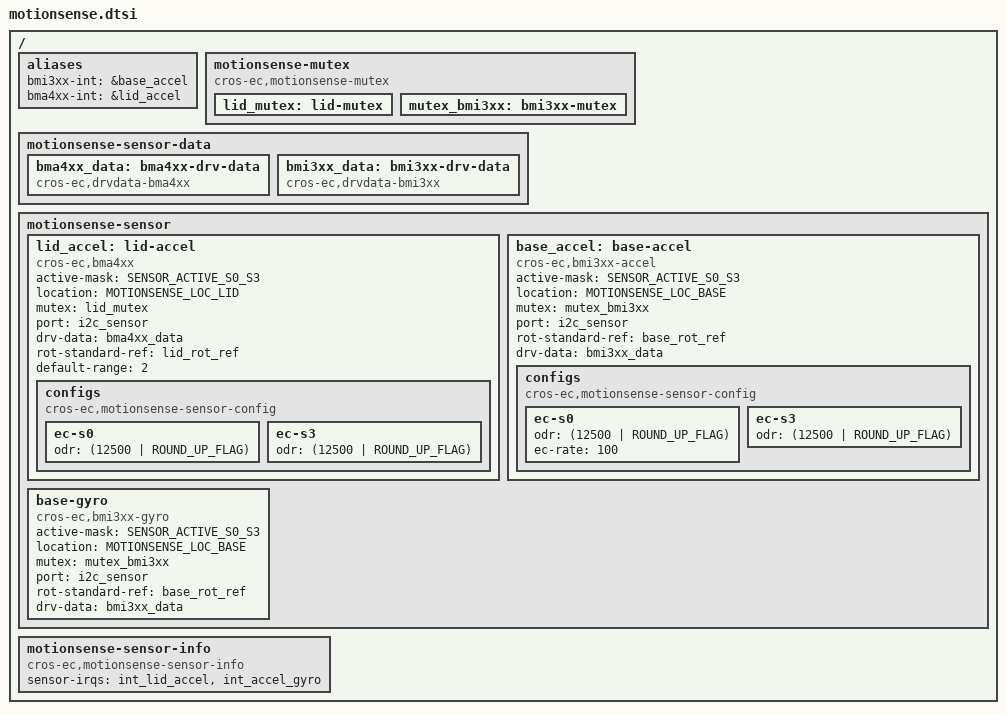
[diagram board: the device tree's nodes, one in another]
/* Copyright 2022 The ChromiumOS Authors
 * Use of this source code is governed by a BSD-style license that can be
 * found in the LICENSE file.
 */

#include <dt-bindings/motionsense/utils.h>


/ {
	aliases {
		/*
		 * motion sense's <>_INT_EVENT is handled
		 * by alias. Using the alias, each driver creates
		 * its own <>_INT_EVENT.
		 */
		bmi3xx-int = &base_accel;
		bma4xx-int = &lid_accel;
	};

	/*
	 * Declare mutexes used by sensor drivers.
	 * A mutex node is used to create an instance of mutex_t.
	 * A mutex node is referenced by a sensor node if the
	 * corresponding sensor driver needs to use the
	 * instance of the mutex.
	 */
	motionsense-mutex {
		compatible = "cros-ec,motionsense-mutex";
		lid_mutex: lid-mutex {
		};

		mutex_bmi3xx: bmi3xx-mutex {
		};
	};

	/*
	 * Driver specific data. A driver-specific data can be shared with
	 * different motion sensors while they are using the same driver.
	 *
	 * If a node's compatible starts with "cros-ec,accelgyro-", it is for
	 * a common structure defined in accelgyro.h.
	 * e.g) compatible = "cros-ec,accelgyro-als-drv-data" is for
	 * "struct als_drv_data_t" in accelgyro.h
	 */
	motionsense-sensor-data {
		bma4xx_data: bma4xx-drv-data {
			compatible = "cros-ec,drvdata-bma4xx";
			status = "okay";
		};

		bmi3xx_data: bmi3xx-drv-data {
			compatible = "cros-ec,drvdata-bmi3xx";
			status = "okay";
		};
	};

	/*
	 * List of motion sensors that creates motion_sensors array.
	 * The nodelabel "lid_accel" and "base_accel" are used to indicate
	 * motion sensor IDs for lid angle calculation.
	 */
	motionsense-sensor {
		lid_accel: lid-accel {
			compatible = "cros-ec,bma4xx";
			status = "okay";

			active-mask = "SENSOR_ACTIVE_S0_S3";
			location = "MOTIONSENSE_LOC_LID";
			mutex = <&lid_mutex>;
			port = <&i2c_sensor>;
			drv-data = <&bma4xx_data>;
			rot-standard-ref = <&lid_rot_ref>;
			default-range = <2>;
			configs {
				compatible =
					"cros-ec,motionsense-sensor-config";
				ec-s0 {
					odr = <(12500 | ROUND_UP_FLAG)>;
				};
				ec-s3 {
					odr = <(12500 | ROUND_UP_FLAG)>;
				};
			};
		};

		base_accel: base-accel {
			compatible = "cros-ec,bmi3xx-accel";
			status = "okay";

			active-mask = "SENSOR_ACTIVE_S0_S3";
			location = "MOTIONSENSE_LOC_BASE";
			mutex = <&mutex_bmi3xx>;
			port = <&i2c_sensor>;
			rot-standard-ref = <&base_rot_ref>;
			drv-data = <&bmi3xx_data>;

			configs {
				compatible =
					"cros-ec,motionsense-sensor-config";
				ec-s0 {
					odr = <(12500 | ROUND_UP_FLAG)>;
					ec-rate = <100>;
				};
				ec-s3 {
					odr = <(12500 | ROUND_UP_FLAG)>;
				};
			};
		};

		base-gyro {
			compatible = "cros-ec,bmi3xx-gyro";
			status = "okay";

			active-mask = "SENSOR_ACTIVE_S0_S3";
			location = "MOTIONSENSE_LOC_BASE";
			mutex = <&mutex_bmi3xx>;
			port = <&i2c_sensor>;
			rot-standard-ref = <&base_rot_ref>;
			drv-data = <&bmi3xx_data>;
		};
	};

	motionsense-sensor-info {
		compatible = "cros-ec,motionsense-sensor-info";

		/*
		 * list of GPIO interrupts that have to
		 * be enabled at initial stage
		 */
		sensor-irqs = <&int_lid_accel &int_accel_gyro>;
	};
};
